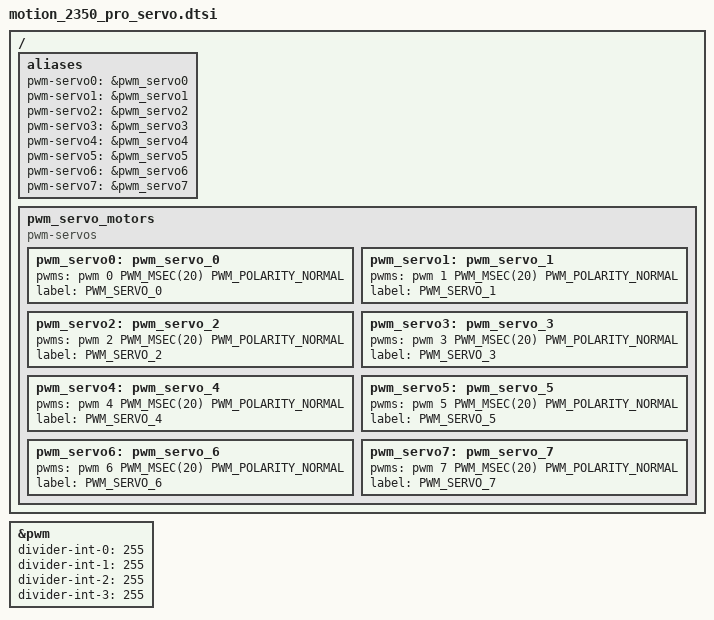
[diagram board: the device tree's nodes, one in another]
/*
 * Copyright (c) 2026 TiaC Systems
 * SPDX-License-Identifier: Apache-2.0
 */

#include <zephyr/dt-bindings/pwm/pwm.h>

/ {
	aliases {
		pwm-servo0 = &pwm_servo0;
		pwm-servo1 = &pwm_servo1;
		pwm-servo2 = &pwm_servo2;
		pwm-servo3 = &pwm_servo3;
		pwm-servo4 = &pwm_servo4;
		pwm-servo5 = &pwm_servo5;
		pwm-servo6 = &pwm_servo6;
		pwm-servo7 = &pwm_servo7;
	};

	pwm_servo_motors {
		compatible = "pwm-servos";
		status = "okay";

		pwm_servo0: pwm_servo_0 {
			pwms = <&pwm 0 PWM_MSEC(20) PWM_POLARITY_NORMAL>;
			label = "PWM_SERVO_0";
		};
		pwm_servo1: pwm_servo_1 {
			pwms = <&pwm 1 PWM_MSEC(20) PWM_POLARITY_NORMAL>;
			label = "PWM_SERVO_1";
		};
		pwm_servo2: pwm_servo_2 {
			pwms = <&pwm 2 PWM_MSEC(20) PWM_POLARITY_NORMAL>;
			label = "PWM_SERVO_2";
		};
		pwm_servo3: pwm_servo_3 {
			pwms = <&pwm 3 PWM_MSEC(20) PWM_POLARITY_NORMAL>;
			label = "PWM_SERVO_3";
		};
		pwm_servo4: pwm_servo_4 {
			pwms = <&pwm 4 PWM_MSEC(20) PWM_POLARITY_NORMAL>;
			label = "PWM_SERVO_4";
		};
		pwm_servo5: pwm_servo_5 {
			pwms = <&pwm 5 PWM_MSEC(20) PWM_POLARITY_NORMAL>;
			label = "PWM_SERVO_5";
		};
		pwm_servo6: pwm_servo_6 {
			pwms = <&pwm 6 PWM_MSEC(20) PWM_POLARITY_NORMAL>;
			label = "PWM_SERVO_6";
		};
		pwm_servo7: pwm_servo_7 {
			pwms = <&pwm 7 PWM_MSEC(20) PWM_POLARITY_NORMAL>;
			label = "PWM_SERVO_7";
		};
	};
};

&pwm {
	divider-int-0 = <255>;
	divider-int-1 = <255>;
	divider-int-2 = <255>;
	divider-int-3 = <255>;
};
